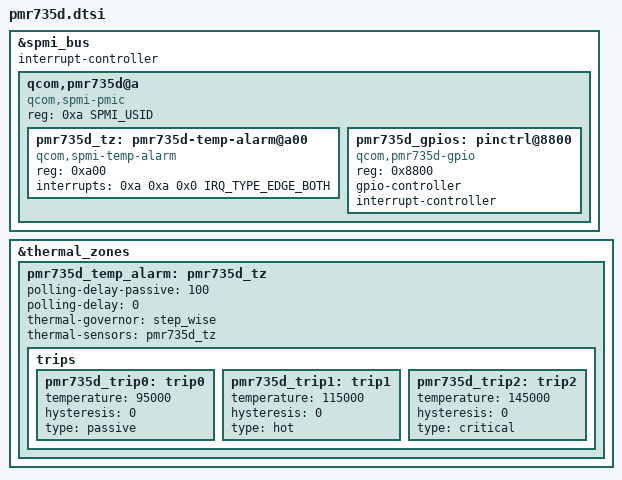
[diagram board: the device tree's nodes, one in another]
// SPDX-License-Identifier: BSD-3-Clause
/*
 * Copyright (c) 2022-2024 Qualcomm Innovation Center, Inc. All rights reserved.
 */

#include <dt-bindings/interrupt-controller/irq.h>
#include <dt-bindings/spmi/spmi.h>

&spmi_bus {
	#address-cells = <2>;
	#size-cells = <0>;
	interrupt-controller;
	#interrupt-cells = <4>;

	qcom,pmr735d@a {
		compatible = "qcom,spmi-pmic";
		reg = <0xa SPMI_USID>;
		#address-cells = <1>;
		#size-cells = <0>;

		pmr735d_tz: pmr735d-temp-alarm@a00 {
			compatible = "qcom,spmi-temp-alarm";
			reg = <0xa00>;
			interrupts = <0xa 0xa 0x0 IRQ_TYPE_EDGE_BOTH>;
			#thermal-sensor-cells = <0>;
		};

		pmr735d_gpios: pinctrl@8800 {
			compatible = "qcom,pmr735d-gpio";
			reg = <0x8800>;
			gpio-controller;
			#gpio-cells = <2>;
			interrupt-controller;
			#interrupt-cells = <2>;
		};
	};
};

&thermal_zones {
	pmr735d_temp_alarm: pmr735d_tz {
		polling-delay-passive = <100>;
		polling-delay = <0>;
		thermal-governor = "step_wise";
		thermal-sensors = <&pmr735d_tz>;

		trips {
			pmr735d_trip0: trip0 {
				temperature = <95000>;
				hysteresis = <0>;
				type = "passive";
			};

			pmr735d_trip1: trip1 {
				temperature = <115000>;
				hysteresis = <0>;
				type = "hot";
			};

			pmr735d_trip2: trip2 {
				temperature = <145000>;
				hysteresis = <0>;
				type = "critical";
			};
		};
	};
};
